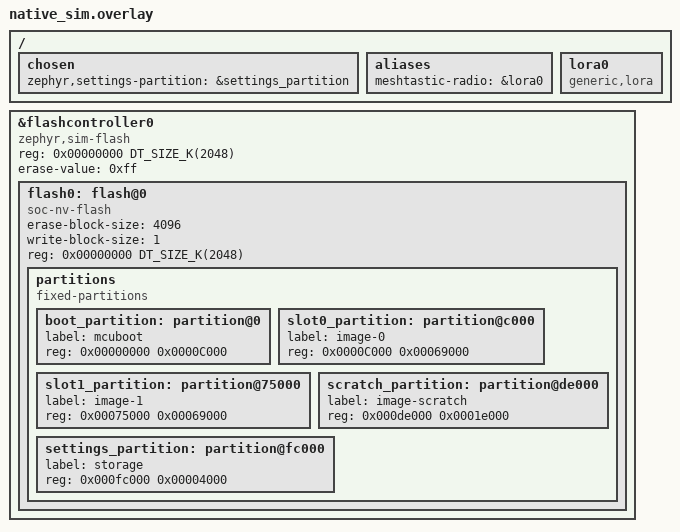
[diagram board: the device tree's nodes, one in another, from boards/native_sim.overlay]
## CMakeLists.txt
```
# SPDX-License-Identifier: Apache-2.0
#set_property(GLOBAL PROPERTY GLOBAL_DEPENDS_DEBUG_MODE 1)
set(CMAKE_VERBOSE_MAKEFILE on)

cmake_minimum_required(VERSION 3.20.0)

find_package(Zephyr REQUIRED HINTS $ENV{ZEPHYR_BASE})
project(lvgl)


FILE(GLOB app_sources src/*.c)
target_sources(app PRIVATE ${app_sources})
```

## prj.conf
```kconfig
CONFIG_MESHTASTIC=y
CONFIG_MESHTASTIC_SHELL=y

CONFIG_LOG=y
CONFIG_SHELL=y

CONFIG_DISK_ACCESS=y
CONFIG_MPU_ALLOW_FLASH_WRITE=y
CONFIG_FLASH_PAGE_LAYOUT=y

CONFIG_SETTINGS_LOG_LEVEL_DBG=y
CONFIG_SETTINGS=y
CONFIG_SETTINGS_SHELL=y
CONFIG_SETTINGS_FCB=y
CONFIG_FCB=y
CONFIG_FLASH_MAP=y
CONFIG_FLASH_SIMULATOR=y
CONFIG_FLASH=y
CONFIG_FLASH_SHELL=y
```

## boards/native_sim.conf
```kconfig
CONFIG_ASAN=y
CONFIG_UART_NATIVE_POSIX=y
CONFIG_GENERIC_LORA=y
```

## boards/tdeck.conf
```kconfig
CONFIG_SX1262=y
```

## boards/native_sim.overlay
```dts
/ {
	chosen {
		zephyr,settings-partition = &settings_partition;

	};
	aliases{
		meshtastic-radio = &lora0;
	};

	lora0: lora0 {
		status = "okay";
		compatible = "generic,lora";
	};
};

&flashcontroller0 {
	status="okay";
	compatible = "zephyr,sim-flash";
	reg = <0x00000000 DT_SIZE_K(2048)>;

	#address-cells = <1>;
	#size-cells = <1>;
	erase-value = <0xff>;

	flash0: flash@0 {
		status = "okay";
		compatible = "soc-nv-flash";
		erase-block-size = <4096>;
		write-block-size = <1>;
		reg = <0x00000000 DT_SIZE_K(2048)>;

		partitions {
			compatible = "fixed-partitions";
			#address-cells = <1>;
			#size-cells = <1>;

			boot_partition: partition@0 {
				label = "mcuboot";
				reg = <0x00000000 0x0000C000>;
			};
			slot0_partition: partition@c000 {
				label = "image-0";
				reg = <0x0000C000 0x00069000>;
			};
			slot1_partition: partition@75000 {
				label = "image-1";
				reg = <0x00075000 0x00069000>;
			};
			scratch_partition: partition@de000 {
				label = "image-scratch";
				reg = <0x000de000 0x0001e000>;
			};
			settings_partition: partition@fc000 {
				label = "storage";
				reg = <0x000fc000 0x00004000>;
			};
		};
	};
};
```

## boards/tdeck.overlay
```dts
/ {
	aliases {
		lora0 = &sx1262;
	}
};
```

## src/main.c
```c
#include <stdio.h>
#include <string.h>
#include <zephyr/device.h>
#include <zephyr/devicetree.h>
#include <zephyr/drivers/display.h>
#include <zephyr/drivers/gpio.h>
#include <zephyr/dt-bindings/input/input-event-codes.h>
#include <zephyr/input/input.h>
#include <zephyr/kernel.h>

#define LOG_LEVEL CONFIG_LOG_DEFAULT_LEVEL
#include <zephyr/logging/log.h>

LOG_MODULE_REGISTER(app);
int main(){
	printk("Hello\n");
}
```
